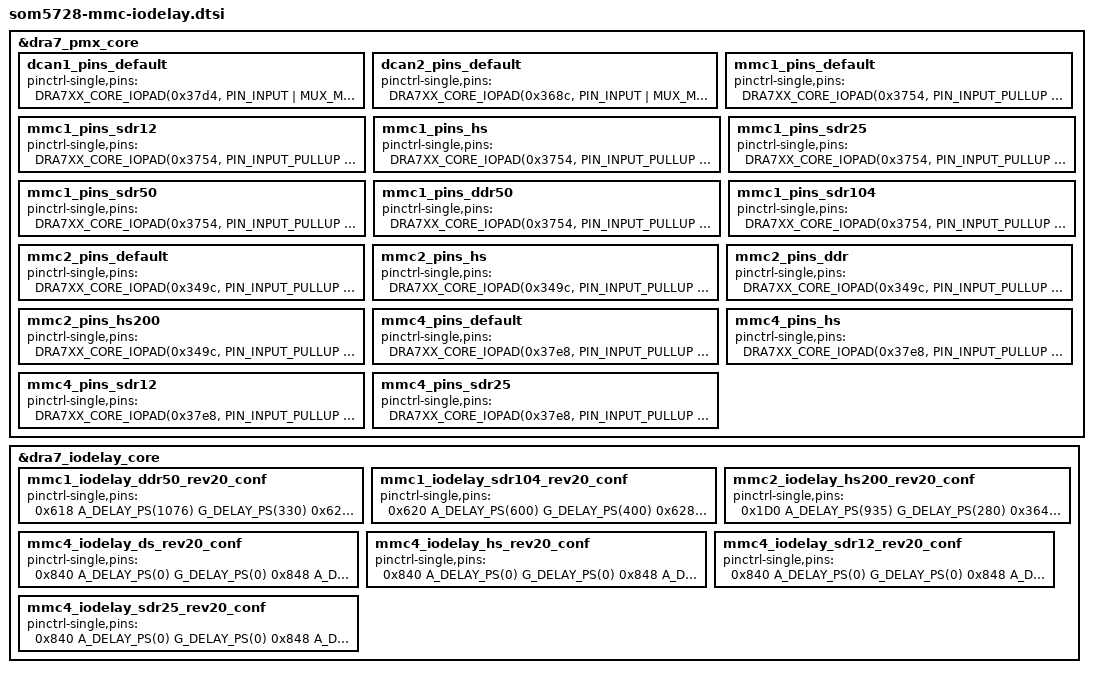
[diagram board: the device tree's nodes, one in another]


// maybe we put all the GPIOS here as defines ?



&dra7_pmx_core {

	dcan1_pins_default: dcan1_pins_default {  
		pinctrl-single,pins = <
			DRA7XX_CORE_IOPAD(0x37d4, PIN_INPUT | MUX_MODE15) 	/* (Errata i893) dcan1_rx.dcan1_rx */
			DRA7XX_CORE_IOPAD(0x37d0, PIN_OUTPUT | MUX_MODE0) 	/* dcan1_tx.dcan1_tx */
		>;
	};

	dcan2_pins_default: dcan2_pins_default {
		pinctrl-single,pins = <
			DRA7XX_CORE_IOPAD(0x368c, PIN_INPUT | MUX_MODE15) 	/* (Errata i893) gpio6_15.dcan2_rx */
			DRA7XX_CORE_IOPAD(0x3688, PIN_OUTPUT | MUX_MODE2) 	/* gpio6_14.dcan2_tx */
		>;
	};

	mmc1_pins_default: mmc1_pins_default {
		pinctrl-single,pins = <
			DRA7XX_CORE_IOPAD(0x3754, PIN_INPUT_PULLUP | MUX_MODE0) 	/* mmc1_clk.mmc1_clk */
			DRA7XX_CORE_IOPAD(0x3758, PIN_INPUT_PULLUP | MUX_MODE0) 	/* mmc1_cmd.mmc1_cmd */
			DRA7XX_CORE_IOPAD(0x375c, PIN_INPUT_PULLUP | MUX_MODE0) 	/* mmc1_dat0.mmc1_dat0 */
			DRA7XX_CORE_IOPAD(0x3760, PIN_INPUT_PULLUP | MUX_MODE0) 	/* mmc1_dat1.mmc1_dat1 */
			DRA7XX_CORE_IOPAD(0x3764, PIN_INPUT_PULLUP | MUX_MODE0) 	/* mmc1_dat2.mmc1_dat2 */
			DRA7XX_CORE_IOPAD(0x3768, PIN_INPUT_PULLUP | MUX_MODE0) 	/* mmc1_dat3.mmc1_dat3 */
			DRA7XX_CORE_IOPAD(0x376c, PIN_INPUT_PULLUP | MUX_MODE0) 	/* mmc1_sdcd.mmc1_sdcd */
		>;
	};

	mmc1_pins_sdr12: mmc1_pins_sdr12 {
		pinctrl-single,pins = <
			DRA7XX_CORE_IOPAD(0x3754, PIN_INPUT_PULLUP | MUX_MODE0) 	/* mmc1_clk.mmc1_clk */
			DRA7XX_CORE_IOPAD(0x3758, PIN_INPUT_PULLUP | MUX_MODE0) 	/* mmc1_cmd.mmc1_cmd */
			DRA7XX_CORE_IOPAD(0x375c, PIN_INPUT_PULLUP | MUX_MODE0) 	/* mmc1_dat0.mmc1_dat0 */
			DRA7XX_CORE_IOPAD(0x3760, PIN_INPUT_PULLUP | MUX_MODE0) 	/* mmc1_dat1.mmc1_dat1 */
			DRA7XX_CORE_IOPAD(0x3764, PIN_INPUT_PULLUP | MUX_MODE0) 	/* mmc1_dat2.mmc1_dat2 */
			DRA7XX_CORE_IOPAD(0x3768, PIN_INPUT_PULLUP | MUX_MODE0) 	/* mmc1_dat3.mmc1_dat3 */
			DRA7XX_CORE_IOPAD(0x376c, PIN_INPUT_PULLUP | MUX_MODE0) 	/* mmc1_sdcd.mmc1_sdcd */
		>;
	};

    
    mmc1_pins_hs: mmc1_pins_hs {
		pinctrl-single,pins = <
			DRA7XX_CORE_IOPAD(0x3754, PIN_INPUT_PULLUP | MUX_VIRTUAL_MODE11 | MUX_MODE0) 	/* mmc1_clk.mmc1_clk */
			DRA7XX_CORE_IOPAD(0x3758, PIN_INPUT_PULLUP | MUX_VIRTUAL_MODE11 | MUX_MODE0) 	/* mmc1_cmd.mmc1_cmd */
			DRA7XX_CORE_IOPAD(0x375c, PIN_INPUT_PULLUP | MUX_VIRTUAL_MODE11 | MUX_MODE0) 	/* mmc1_dat0.mmc1_dat0 */
			DRA7XX_CORE_IOPAD(0x3760, PIN_INPUT_PULLUP | MUX_VIRTUAL_MODE11 | MUX_MODE0) 	/* mmc1_dat1.mmc1_dat1 */
			DRA7XX_CORE_IOPAD(0x3764, PIN_INPUT_PULLUP | MUX_VIRTUAL_MODE11 | MUX_MODE0) 	/* mmc1_dat2.mmc1_dat2 */
			DRA7XX_CORE_IOPAD(0x3768, PIN_INPUT_PULLUP | MUX_VIRTUAL_MODE11 | MUX_MODE0) 	/* mmc1_dat3.mmc1_dat3 */
		>;
	};
    
	mmc1_pins_sdr25: mmc1_pins_sdr25 {
		pinctrl-single,pins = <
			DRA7XX_CORE_IOPAD(0x3754, PIN_INPUT_PULLUP | MUX_VIRTUAL_MODE11 | MUX_MODE0) 	/* mmc1_clk.mmc1_clk */
			DRA7XX_CORE_IOPAD(0x3758, PIN_INPUT_PULLUP | MUX_VIRTUAL_MODE11 | MUX_MODE0) 	/* mmc1_cmd.mmc1_cmd */
			DRA7XX_CORE_IOPAD(0x375c, PIN_INPUT_PULLUP | MUX_VIRTUAL_MODE11 | MUX_MODE0) 	/* mmc1_dat0.mmc1_dat0 */
			DRA7XX_CORE_IOPAD(0x3760, PIN_INPUT_PULLUP | MUX_VIRTUAL_MODE11 | MUX_MODE0) 	/* mmc1_dat1.mmc1_dat1 */
			DRA7XX_CORE_IOPAD(0x3764, PIN_INPUT_PULLUP | MUX_VIRTUAL_MODE11 | MUX_MODE0) 	/* mmc1_dat2.mmc1_dat2 */
			DRA7XX_CORE_IOPAD(0x3768, PIN_INPUT_PULLUP | MUX_VIRTUAL_MODE11 | MUX_MODE0) 	/* mmc1_dat3.mmc1_dat3 */
		>;
	};    
    
    mmc1_pins_sdr50: mmc1_pins_sdr50 {
		pinctrl-single,pins = <
			DRA7XX_CORE_IOPAD(0x3754, PIN_INPUT_PULLUP | MUX_VIRTUAL_MODE10 | MUX_MODE0) 	/* mmc1_clk.mmc1_clk */
			DRA7XX_CORE_IOPAD(0x3758, PIN_INPUT_PULLUP | MUX_VIRTUAL_MODE10 | MUX_MODE0) 	/* mmc1_cmd.mmc1_cmd */
			DRA7XX_CORE_IOPAD(0x375c, PIN_INPUT_PULLUP | MUX_VIRTUAL_MODE10 | MUX_MODE0) 	/* mmc1_dat0.mmc1_dat0 */
			DRA7XX_CORE_IOPAD(0x3760, PIN_INPUT_PULLUP | MUX_VIRTUAL_MODE10 | MUX_MODE0) 	/* mmc1_dat1.mmc1_dat1 */
			DRA7XX_CORE_IOPAD(0x3764, PIN_INPUT_PULLUP | MUX_VIRTUAL_MODE10 | MUX_MODE0) 	/* mmc1_dat2.mmc1_dat2 */
			DRA7XX_CORE_IOPAD(0x3768, PIN_INPUT_PULLUP | MUX_VIRTUAL_MODE10 | MUX_MODE0) 	/* mmc1_dat3.mmc1_dat3 */
		>;
	};
    
    
	mmc1_pins_ddr50: mmc1_pins_ddr50 {
		pinctrl-single,pins = <
			DRA7XX_CORE_IOPAD(0x3754, PIN_INPUT_PULLUP | MODE_SELECT | MUX_MODE0) 	/* mmc1_clk.mmc1_clk */
			DRA7XX_CORE_IOPAD(0x3758, PIN_INPUT_PULLUP | MODE_SELECT | MUX_MODE0) 	/* mmc1_cmd.mmc1_cmd */
			DRA7XX_CORE_IOPAD(0x375c, PIN_INPUT_PULLUP | MODE_SELECT | MUX_MODE0) 	/* mmc1_dat0.mmc1_dat0 */
			DRA7XX_CORE_IOPAD(0x3760, PIN_INPUT_PULLUP | MODE_SELECT | MUX_MODE0) 	/* mmc1_dat1.mmc1_dat1 */
			DRA7XX_CORE_IOPAD(0x3764, PIN_INPUT_PULLUP | MODE_SELECT | MUX_MODE0) 	/* mmc1_dat2.mmc1_dat2 */
			DRA7XX_CORE_IOPAD(0x3768, PIN_INPUT_PULLUP | MODE_SELECT | MUX_MODE0) 	/* mmc1_dat3.mmc1_dat3 */
		>;
	};


	mmc1_pins_sdr104: mmc1_pins_sdr104 {
		pinctrl-single,pins = <
			DRA7XX_CORE_IOPAD(0x3754, PIN_INPUT_PULLUP | MODE_SELECT | MUX_MODE0) 	/* mmc1_clk.mmc1_clk */
			DRA7XX_CORE_IOPAD(0x3758, PIN_INPUT_PULLUP | MODE_SELECT | MUX_MODE0) 	/* mmc1_cmd.mmc1_cmd */
			DRA7XX_CORE_IOPAD(0x375c, PIN_INPUT_PULLUP | MODE_SELECT | MUX_MODE0) 	/* mmc1_dat0.mmc1_dat0 */
			DRA7XX_CORE_IOPAD(0x3760, PIN_INPUT_PULLUP | MODE_SELECT | MUX_MODE0) 	/* mmc1_dat1.mmc1_dat1 */
			DRA7XX_CORE_IOPAD(0x3764, PIN_INPUT_PULLUP | MODE_SELECT | MUX_MODE0) 	/* mmc1_dat2.mmc1_dat2 */
			DRA7XX_CORE_IOPAD(0x3768, PIN_INPUT_PULLUP | MODE_SELECT | MUX_MODE0) 	/* mmc1_dat3.mmc1_dat3 */
		>;
	};
    

    
    
    

	mmc2_pins_default: mmc2_pins_default {
		pinctrl-single,pins = <
			DRA7XX_CORE_IOPAD(0x349c, PIN_INPUT_PULLUP | MUX_MODE1) 	/* gpmc_a23.mmc2_clk */
			DRA7XX_CORE_IOPAD(0x34b0, PIN_INPUT_PULLUP | MUX_MODE1) 	/* gpmc_cs1.mmc2_cmd */
			DRA7XX_CORE_IOPAD(0x34a0, PIN_INPUT_PULLUP | MUX_MODE1) 	/* gpmc_a24.mmc2_dat0 */
			DRA7XX_CORE_IOPAD(0x34a4, PIN_INPUT_PULLUP | MUX_MODE1) 	/* gpmc_a25.mmc2_dat1 */
			DRA7XX_CORE_IOPAD(0x34a8, PIN_INPUT_PULLUP | MUX_MODE1) 	/* gpmc_a26.mmc2_dat2 */
			DRA7XX_CORE_IOPAD(0x34ac, PIN_INPUT_PULLUP | MUX_MODE1) 	/* gpmc_a27.mmc2_dat3 */
			DRA7XX_CORE_IOPAD(0x348c, PIN_INPUT_PULLUP | MUX_MODE1) 	/* gpmc_a19.mmc2_dat4 */
			DRA7XX_CORE_IOPAD(0x3490, PIN_INPUT_PULLUP | MUX_MODE1) 	/* gpmc_a20.mmc2_dat5 */
			DRA7XX_CORE_IOPAD(0x3494, PIN_INPUT_PULLUP | MUX_MODE1) 	/* gpmc_a21.mmc2_dat6 */
			DRA7XX_CORE_IOPAD(0x3498, PIN_INPUT_PULLUP | MUX_MODE1) 	/* gpmc_a22.mmc2_dat7 */
		>;
	};

	mmc2_pins_hs: mmc2_pins_hs {
		pinctrl-single,pins = <
			DRA7XX_CORE_IOPAD(0x349c, PIN_INPUT_PULLUP | MUX_MODE1) 	/* gpmc_a23.mmc2_clk */
			DRA7XX_CORE_IOPAD(0x34b0, PIN_INPUT_PULLUP | MUX_MODE1) 	/* gpmc_cs1.mmc2_cmd */
			DRA7XX_CORE_IOPAD(0x34a0, PIN_INPUT_PULLUP | MUX_MODE1) 	/* gpmc_a24.mmc2_dat0 */
			DRA7XX_CORE_IOPAD(0x34a4, PIN_INPUT_PULLUP | MUX_MODE1) 	/* gpmc_a25.mmc2_dat1 */
			DRA7XX_CORE_IOPAD(0x34a8, PIN_INPUT_PULLUP | MUX_MODE1) 	/* gpmc_a26.mmc2_dat2 */
			DRA7XX_CORE_IOPAD(0x34ac, PIN_INPUT_PULLUP | MUX_MODE1) 	/* gpmc_a27.mmc2_dat3 */
			DRA7XX_CORE_IOPAD(0x348c, PIN_INPUT_PULLUP | MUX_MODE1) 	/* gpmc_a19.mmc2_dat4 */
			DRA7XX_CORE_IOPAD(0x3490, PIN_INPUT_PULLUP | MUX_MODE1) 	/* gpmc_a20.mmc2_dat5 */
			DRA7XX_CORE_IOPAD(0x3494, PIN_INPUT_PULLUP | MUX_MODE1) 	/* gpmc_a21.mmc2_dat6 */
			DRA7XX_CORE_IOPAD(0x3498, PIN_INPUT_PULLUP | MUX_MODE1) 	/* gpmc_a22.mmc2_dat7 */
		>;
	};

	mmc2_pins_ddr: mmc2_pins_ddr {
		pinctrl-single,pins = <
			DRA7XX_CORE_IOPAD(0x349c, PIN_INPUT_PULLUP | MUX_MODE1) 	/* gpmc_a23.mmc2_clk */
			DRA7XX_CORE_IOPAD(0x34b0, PIN_INPUT_PULLUP | MUX_MODE1) 	/* gpmc_cs1.mmc2_cmd */
			DRA7XX_CORE_IOPAD(0x34a0, PIN_INPUT_PULLUP | MUX_MODE1) 	/* gpmc_a24.mmc2_dat0 */
			DRA7XX_CORE_IOPAD(0x34a4, PIN_INPUT_PULLUP | MUX_MODE1) 	/* gpmc_a25.mmc2_dat1 */
			DRA7XX_CORE_IOPAD(0x34a8, PIN_INPUT_PULLUP | MUX_MODE1) 	/* gpmc_a26.mmc2_dat2 */
			DRA7XX_CORE_IOPAD(0x34ac, PIN_INPUT_PULLUP | MUX_MODE1) 	/* gpmc_a27.mmc2_dat3 */
			DRA7XX_CORE_IOPAD(0x348c, PIN_INPUT_PULLUP | MUX_MODE1) 	/* gpmc_a19.mmc2_dat4 */
			DRA7XX_CORE_IOPAD(0x3490, PIN_INPUT_PULLUP | MUX_MODE1) 	/* gpmc_a20.mmc2_dat5 */
			DRA7XX_CORE_IOPAD(0x3494, PIN_INPUT_PULLUP | MUX_MODE1) 	/* gpmc_a21.mmc2_dat6 */
			DRA7XX_CORE_IOPAD(0x3498, PIN_INPUT_PULLUP | MUX_MODE1) 	/* gpmc_a22.mmc2_dat7 */
		>;
	};

	mmc2_pins_hs200: mmc2_pins_hs200 {
		pinctrl-single,pins = <
			DRA7XX_CORE_IOPAD(0x349c, PIN_INPUT_PULLUP | MODE_SELECT | MUX_MODE1) 	/* gpmc_a23.mmc2_clk */
			DRA7XX_CORE_IOPAD(0x34b0, PIN_INPUT_PULLUP | MODE_SELECT | MUX_MODE1) 	/* gpmc_cs1.mmc2_cmd */
			DRA7XX_CORE_IOPAD(0x34a0, PIN_INPUT_PULLUP | MODE_SELECT | MUX_MODE1) 	/* gpmc_a24.mmc2_dat0 */
			DRA7XX_CORE_IOPAD(0x34a4, PIN_INPUT_PULLUP | MODE_SELECT | MUX_MODE1) 	/* gpmc_a25.mmc2_dat1 */
			DRA7XX_CORE_IOPAD(0x34a8, PIN_INPUT_PULLUP | MODE_SELECT | MUX_MODE1) 	/* gpmc_a26.mmc2_dat2 */
			DRA7XX_CORE_IOPAD(0x34ac, PIN_INPUT_PULLUP | MODE_SELECT | MUX_MODE1) 	/* gpmc_a27.mmc2_dat3 */
			DRA7XX_CORE_IOPAD(0x348c, PIN_INPUT_PULLUP | MODE_SELECT | MUX_MODE1) 	/* gpmc_a19.mmc2_dat4 */
			DRA7XX_CORE_IOPAD(0x3490, PIN_INPUT_PULLUP | MODE_SELECT | MUX_MODE1) 	/* gpmc_a20.mmc2_dat5 */
			DRA7XX_CORE_IOPAD(0x3494, PIN_INPUT_PULLUP | MODE_SELECT | MUX_MODE1) 	/* gpmc_a21.mmc2_dat6 */
			DRA7XX_CORE_IOPAD(0x3498, PIN_INPUT_PULLUP | MODE_SELECT | MUX_MODE1) 	/* gpmc_a22.mmc2_dat7 */
		>;
	};

	mmc4_pins_default: mmc4_pins_default {
		pinctrl-single,pins = <
			DRA7XX_CORE_IOPAD(0x37e8, PIN_INPUT_PULLUP | MODE_SELECT | MUX_MODE3) 	/* uart1_ctsn.mmc4_clk */
			DRA7XX_CORE_IOPAD(0x37ec, PIN_INPUT_PULLUP | MODE_SELECT | MUX_MODE3) 	/* uart1_rtsn.mmc4_cmd */
			DRA7XX_CORE_IOPAD(0x37f0, PIN_INPUT_PULLUP | MODE_SELECT | MUX_MODE3) 	/* uart2_rxd.mmc4_dat0 */
			DRA7XX_CORE_IOPAD(0x37f4, PIN_INPUT_PULLUP | MODE_SELECT | MUX_MODE3) 	/* uart2_txd.mmc4_dat1 */
			DRA7XX_CORE_IOPAD(0x37f8, PIN_INPUT_PULLUP | MODE_SELECT | MUX_MODE3) 	/* uart2_ctsn.mmc4_dat2 */
			DRA7XX_CORE_IOPAD(0x37fc, PIN_INPUT_PULLUP | MODE_SELECT | MUX_MODE3) 	/* uart2_rtsn.mmc4_dat3 */
		>;
	};

	mmc4_pins_hs: mmc4_pins_hs {
		pinctrl-single,pins = <
			DRA7XX_CORE_IOPAD(0x37e8, PIN_INPUT_PULLUP | MODE_SELECT | MUX_MODE3) 	/* uart1_ctsn.mmc4_clk */
			DRA7XX_CORE_IOPAD(0x37ec, PIN_INPUT_PULLUP | MODE_SELECT | MUX_MODE3) 	/* uart1_rtsn.mmc4_cmd */
			DRA7XX_CORE_IOPAD(0x37f0, PIN_INPUT_PULLUP | MODE_SELECT | MUX_MODE3) 	/* uart2_rxd.mmc4_dat0 */
			DRA7XX_CORE_IOPAD(0x37f4, PIN_INPUT_PULLUP | MODE_SELECT | MUX_MODE3) 	/* uart2_txd.mmc4_dat1 */
			DRA7XX_CORE_IOPAD(0x37f8, PIN_INPUT_PULLUP | MODE_SELECT | MUX_MODE3) 	/* uart2_ctsn.mmc4_dat2 */
			DRA7XX_CORE_IOPAD(0x37fc, PIN_INPUT_PULLUP | MODE_SELECT | MUX_MODE3) 	/* uart2_rtsn.mmc4_dat3 */
		>;
	};

	mmc4_pins_sdr12: mmc4_pins_sdr12 {
		pinctrl-single,pins = <
			DRA7XX_CORE_IOPAD(0x37e8, PIN_INPUT_PULLUP | MODE_SELECT | MUX_MODE3) 	/* uart1_ctsn.mmc4_clk */
			DRA7XX_CORE_IOPAD(0x37ec, PIN_INPUT_PULLUP | MODE_SELECT | MUX_MODE3) 	/* uart1_rtsn.mmc4_cmd */
			DRA7XX_CORE_IOPAD(0x37f0, PIN_INPUT_PULLUP | MODE_SELECT | MUX_MODE3) 	/* uart2_rxd.mmc4_dat0 */
			DRA7XX_CORE_IOPAD(0x37f4, PIN_INPUT_PULLUP | MODE_SELECT | MUX_MODE3) 	/* uart2_txd.mmc4_dat1 */
			DRA7XX_CORE_IOPAD(0x37f8, PIN_INPUT_PULLUP | MODE_SELECT | MUX_MODE3) 	/* uart2_ctsn.mmc4_dat2 */
			DRA7XX_CORE_IOPAD(0x37fc, PIN_INPUT_PULLUP | MODE_SELECT | MUX_MODE3) 	/* uart2_rtsn.mmc4_dat3 */
		>;
	};

	mmc4_pins_sdr25: mmc4_pins_sdr25 {
		pinctrl-single,pins = <
			DRA7XX_CORE_IOPAD(0x37e8, PIN_INPUT_PULLUP | MODE_SELECT | MUX_MODE3) 	/* uart1_ctsn.mmc4_clk */
			DRA7XX_CORE_IOPAD(0x37ec, PIN_INPUT_PULLUP | MODE_SELECT | MUX_MODE3) 	/* uart1_rtsn.mmc4_cmd */
			DRA7XX_CORE_IOPAD(0x37f0, PIN_INPUT_PULLUP | MODE_SELECT | MUX_MODE3) 	/* uart2_rxd.mmc4_dat0 */
			DRA7XX_CORE_IOPAD(0x37f4, PIN_INPUT_PULLUP | MODE_SELECT | MUX_MODE3) 	/* uart2_txd.mmc4_dat1 */
			DRA7XX_CORE_IOPAD(0x37f8, PIN_INPUT_PULLUP | MODE_SELECT | MUX_MODE3) 	/* uart2_ctsn.mmc4_dat2 */
			DRA7XX_CORE_IOPAD(0x37fc, PIN_INPUT_PULLUP | MODE_SELECT | MUX_MODE3) 	/* uart2_rtsn.mmc4_dat3 */
		>;
	};

};


/* * DEVICE TREE FORMAT IODELAY * */

&dra7_iodelay_core {

	mmc1_iodelay_ddr50_rev20_conf: mmc1_iodelay_ddr50_rev20_conf {
		pinctrl-single,pins = <
			0x618 A_DELAY_PS(1076)  G_DELAY_PS(330) 	/* CFG_MMC1_CLK_IN */
			0x620 A_DELAY_PS(1271)  G_DELAY_PS(0) 	/* CFG_MMC1_CLK_OUT */
			0x624 A_DELAY_PS(722)  G_DELAY_PS(0) 	/* CFG_MMC1_CMD_IN */
			0x628 A_DELAY_PS(0)  G_DELAY_PS(0) 	/* CFG_MMC1_CMD_OEN */
			0x62C A_DELAY_PS(0)  G_DELAY_PS(0) 	/* CFG_MMC1_CMD_OUT */
			0x630 A_DELAY_PS(751)  G_DELAY_PS(0) 	/* CFG_MMC1_DAT0_IN */
			0x634 A_DELAY_PS(0)  G_DELAY_PS(0) 	/* CFG_MMC1_DAT0_OEN */
			0x638 A_DELAY_PS(20)  G_DELAY_PS(0) 	/* CFG_MMC1_DAT0_OUT */
			0x63C A_DELAY_PS(256)  G_DELAY_PS(0) 	/* CFG_MMC1_DAT1_IN */
			0x640 A_DELAY_PS(0)  G_DELAY_PS(0) 	/* CFG_MMC1_DAT1_OEN */
			0x644 A_DELAY_PS(0)  G_DELAY_PS(0) 	/* CFG_MMC1_DAT1_OUT */
			0x648 A_DELAY_PS(263)  G_DELAY_PS(0) 	/* CFG_MMC1_DAT2_IN */
			0x64C A_DELAY_PS(0)  G_DELAY_PS(0) 	/* CFG_MMC1_DAT2_OEN */
			0x650 A_DELAY_PS(0)  G_DELAY_PS(0) 	/* CFG_MMC1_DAT2_OUT */
			0x654 A_DELAY_PS(0)  G_DELAY_PS(0) 	/* CFG_MMC1_DAT3_IN */
			0x658 A_DELAY_PS(0)  G_DELAY_PS(0) 	/* CFG_MMC1_DAT3_OEN */
			0x65C A_DELAY_PS(0)  G_DELAY_PS(0) 	/* CFG_MMC1_DAT3_OUT */
		>;
	};

	mmc1_iodelay_sdr104_rev20_conf: mmc1_iodelay_sdr104_rev20_conf {
		pinctrl-single,pins = <
			0x620 A_DELAY_PS(600)  G_DELAY_PS(400) 	/* CFG_MMC1_CLK_OUT */
			0x628 A_DELAY_PS(0)  G_DELAY_PS(0) 	/* CFG_MMC1_CMD_OEN */
			0x62C A_DELAY_PS(0)  G_DELAY_PS(0) 	/* CFG_MMC1_CMD_OUT */
			0x634 A_DELAY_PS(0)  G_DELAY_PS(0) 	/* CFG_MMC1_DAT0_OEN */
			0x638 A_DELAY_PS(30)  G_DELAY_PS(0) 	/* CFG_MMC1_DAT0_OUT */
			0x640 A_DELAY_PS(0)  G_DELAY_PS(0) 	/* CFG_MMC1_DAT1_OEN */
			0x644 A_DELAY_PS(0)  G_DELAY_PS(0) 	/* CFG_MMC1_DAT1_OUT */
			0x64C A_DELAY_PS(0)  G_DELAY_PS(0) 	/* CFG_MMC1_DAT2_OEN */
			0x650 A_DELAY_PS(0)  G_DELAY_PS(0) 	/* CFG_MMC1_DAT2_OUT */
			0x658 A_DELAY_PS(0)  G_DELAY_PS(0) 	/* CFG_MMC1_DAT3_OEN */
			0x65C A_DELAY_PS(0)  G_DELAY_PS(0) 	/* CFG_MMC1_DAT3_OUT */
		>;
	};

	mmc2_iodelay_hs200_rev20_conf: mmc2_iodelay_hs200_rev20_conf {
		pinctrl-single,pins = <
			0x1D0 A_DELAY_PS(935)  G_DELAY_PS(280) 	/* CFG_GPMC_A23_OUT */
			0x364 A_DELAY_PS(684)  G_DELAY_PS(0) 	/* CFG_GPMC_CS1_OEN */
			0x368 A_DELAY_PS(76)  G_DELAY_PS(0) 	/* CFG_GPMC_CS1_OUT */
			0x1D8 A_DELAY_PS(621)  G_DELAY_PS(0) 	/* CFG_GPMC_A24_OEN */
			0x1DC A_DELAY_PS(0)  G_DELAY_PS(0) 	/* CFG_GPMC_A24_OUT */
			0x1E4 A_DELAY_PS(183)  G_DELAY_PS(0) 	/* CFG_GPMC_A25_OEN */
			0x1E8 A_DELAY_PS(0)  G_DELAY_PS(0) 	/* CFG_GPMC_A25_OUT */
			0x1F0 A_DELAY_PS(467)  G_DELAY_PS(0) 	/* CFG_GPMC_A26_OEN */
			0x1F4 A_DELAY_PS(0)  G_DELAY_PS(0) 	/* CFG_GPMC_A26_OUT */
			0x1FC A_DELAY_PS(262)  G_DELAY_PS(0) 	/* CFG_GPMC_A27_OEN */
			0x200 A_DELAY_PS(46)  G_DELAY_PS(0) 	/* CFG_GPMC_A27_OUT */
			0x190 A_DELAY_PS(274)  G_DELAY_PS(0) 	/* CFG_GPMC_A19_OEN */
			0x194 A_DELAY_PS(162)  G_DELAY_PS(0) 	/* CFG_GPMC_A19_OUT */
			0x1A8 A_DELAY_PS(401)  G_DELAY_PS(0) 	/* CFG_GPMC_A20_OEN */
			0x1AC A_DELAY_PS(73)  G_DELAY_PS(0) 	/* CFG_GPMC_A20_OUT */
			0x1B4 A_DELAY_PS(465)  G_DELAY_PS(0) 	/* CFG_GPMC_A21_OEN */
			0x1B8 A_DELAY_PS(115)  G_DELAY_PS(0) 	/* CFG_GPMC_A21_OUT */
			0x1C0 A_DELAY_PS(633)  G_DELAY_PS(0) 	/* CFG_GPMC_A22_OEN */
			0x1C4 A_DELAY_PS(47)  G_DELAY_PS(0) 	/* CFG_GPMC_A22_OUT */
		>;
	};

	mmc4_iodelay_ds_rev20_conf: mmc4_iodelay_ds_rev20_conf {
		pinctrl-single,pins = <
			0x840 A_DELAY_PS(0)  G_DELAY_PS(0) 	/* CFG_UART1_CTSN_IN */
			0x848 A_DELAY_PS(0)  G_DELAY_PS(0) 	/* CFG_UART1_CTSN_OUT */
			0x84C A_DELAY_PS(307)  G_DELAY_PS(0) 	/* CFG_UART1_RTSN_IN */
			0x850 A_DELAY_PS(0)  G_DELAY_PS(0) 	/* CFG_UART1_RTSN_OEN */
			0x854 A_DELAY_PS(0)  G_DELAY_PS(0) 	/* CFG_UART1_RTSN_OUT */
			0x888 A_DELAY_PS(683)  G_DELAY_PS(0) 	/* CFG_UART2_RXD_IN */
			0x88C A_DELAY_PS(0)  G_DELAY_PS(0) 	/* CFG_UART2_RXD_OEN */
			0x890 A_DELAY_PS(0)  G_DELAY_PS(0) 	/* CFG_UART2_RXD_OUT */
			0x894 A_DELAY_PS(835)  G_DELAY_PS(0) 	/* CFG_UART2_TXD_IN */
			0x898 A_DELAY_PS(0)  G_DELAY_PS(0) 	/* CFG_UART2_TXD_OEN */
			0x89C A_DELAY_PS(0)  G_DELAY_PS(0) 	/* CFG_UART2_TXD_OUT */
			0x870 A_DELAY_PS(785)  G_DELAY_PS(0) 	/* CFG_UART2_CTSN_IN */
			0x874 A_DELAY_PS(0)  G_DELAY_PS(0) 	/* CFG_UART2_CTSN_OEN */
			0x878 A_DELAY_PS(0)  G_DELAY_PS(0) 	/* CFG_UART2_CTSN_OUT */
			0x87C A_DELAY_PS(613)  G_DELAY_PS(0) 	/* CFG_UART2_RTSN_IN */
			0x880 A_DELAY_PS(0)  G_DELAY_PS(0) 	/* CFG_UART2_RTSN_OEN */
			0x884 A_DELAY_PS(0)  G_DELAY_PS(0) 	/* CFG_UART2_RTSN_OUT */
		>;
	};

	mmc4_iodelay_hs_rev20_conf: mmc4_iodelay_hs_rev20_conf {
		pinctrl-single,pins = <
			0x840 A_DELAY_PS(0)  G_DELAY_PS(0) 	/* CFG_UART1_CTSN_IN */
			0x848 A_DELAY_PS(1147)  G_DELAY_PS(0) 	/* CFG_UART1_CTSN_OUT */
			0x84C A_DELAY_PS(1834)  G_DELAY_PS(0) 	/* CFG_UART1_RTSN_IN */
			0x850 A_DELAY_PS(0)  G_DELAY_PS(0) 	/* CFG_UART1_RTSN_OEN */
			0x854 A_DELAY_PS(0)  G_DELAY_PS(0) 	/* CFG_UART1_RTSN_OUT */
			0x888 A_DELAY_PS(1935)  G_DELAY_PS(128) 	/* CFG_UART2_RXD_IN */
			0x88C A_DELAY_PS(0)  G_DELAY_PS(0) 	/* CFG_UART2_RXD_OEN */
			0x890 A_DELAY_PS(0)  G_DELAY_PS(0) 	/* CFG_UART2_RXD_OUT */
			0x894 A_DELAY_PS(2172)  G_DELAY_PS(44) 	/* CFG_UART2_TXD_IN */
			0x898 A_DELAY_PS(0)  G_DELAY_PS(0) 	/* CFG_UART2_TXD_OEN */
			0x89C A_DELAY_PS(0)  G_DELAY_PS(0) 	/* CFG_UART2_TXD_OUT */
			0x870 A_DELAY_PS(2165)  G_DELAY_PS(0) 	/* CFG_UART2_CTSN_IN */
			0x874 A_DELAY_PS(0)  G_DELAY_PS(0) 	/* CFG_UART2_CTSN_OEN */
			0x878 A_DELAY_PS(0)  G_DELAY_PS(0) 	/* CFG_UART2_CTSN_OUT */
			0x87C A_DELAY_PS(1929)  G_DELAY_PS(64) 	/* CFG_UART2_RTSN_IN */
			0x880 A_DELAY_PS(0)  G_DELAY_PS(0) 	/* CFG_UART2_RTSN_OEN */
			0x884 A_DELAY_PS(0)  G_DELAY_PS(0) 	/* CFG_UART2_RTSN_OUT */
		>;
	};

	mmc4_iodelay_sdr12_rev20_conf: mmc4_iodelay_sdr12_rev20_conf {
		pinctrl-single,pins = <
			0x840 A_DELAY_PS(0)  G_DELAY_PS(0) 	/* CFG_UART1_CTSN_IN */
			0x848 A_DELAY_PS(1147)  G_DELAY_PS(0) 	/* CFG_UART1_CTSN_OUT */
			0x84C A_DELAY_PS(1834)  G_DELAY_PS(0) 	/* CFG_UART1_RTSN_IN */
			0x850 A_DELAY_PS(0)  G_DELAY_PS(0) 	/* CFG_UART1_RTSN_OEN */
			0x854 A_DELAY_PS(0)  G_DELAY_PS(0) 	/* CFG_UART1_RTSN_OUT */
			0x888 A_DELAY_PS(1935)  G_DELAY_PS(128) 	/* CFG_UART2_RXD_IN */
			0x88C A_DELAY_PS(0)  G_DELAY_PS(0) 	/* CFG_UART2_RXD_OEN */
			0x890 A_DELAY_PS(0)  G_DELAY_PS(0) 	/* CFG_UART2_RXD_OUT */
			0x894 A_DELAY_PS(2172)  G_DELAY_PS(44) 	/* CFG_UART2_TXD_IN */
			0x898 A_DELAY_PS(0)  G_DELAY_PS(0) 	/* CFG_UART2_TXD_OEN */
			0x89C A_DELAY_PS(0)  G_DELAY_PS(0) 	/* CFG_UART2_TXD_OUT */
			0x870 A_DELAY_PS(2165)  G_DELAY_PS(0) 	/* CFG_UART2_CTSN_IN */
			0x874 A_DELAY_PS(0)  G_DELAY_PS(0) 	/* CFG_UART2_CTSN_OEN */
			0x878 A_DELAY_PS(0)  G_DELAY_PS(0) 	/* CFG_UART2_CTSN_OUT */
			0x87C A_DELAY_PS(1929)  G_DELAY_PS(64) 	/* CFG_UART2_RTSN_IN */
			0x880 A_DELAY_PS(0)  G_DELAY_PS(0) 	/* CFG_UART2_RTSN_OEN */
			0x884 A_DELAY_PS(0)  G_DELAY_PS(0) 	/* CFG_UART2_RTSN_OUT */
		>;
	};

	mmc4_iodelay_sdr25_rev20_conf: mmc4_iodelay_sdr25_rev20_conf {
		pinctrl-single,pins = <
			0x840 A_DELAY_PS(0)  G_DELAY_PS(0) 	/* CFG_UART1_CTSN_IN */
			0x848 A_DELAY_PS(1147)  G_DELAY_PS(0) 	/* CFG_UART1_CTSN_OUT */
			0x84C A_DELAY_PS(1834)  G_DELAY_PS(0) 	/* CFG_UART1_RTSN_IN */
			0x850 A_DELAY_PS(0)  G_DELAY_PS(0) 	/* CFG_UART1_RTSN_OEN */
			0x854 A_DELAY_PS(0)  G_DELAY_PS(0) 	/* CFG_UART1_RTSN_OUT */
			0x888 A_DELAY_PS(1935)  G_DELAY_PS(128) 	/* CFG_UART2_RXD_IN */
			0x88C A_DELAY_PS(0)  G_DELAY_PS(0) 	/* CFG_UART2_RXD_OEN */
			0x890 A_DELAY_PS(0)  G_DELAY_PS(0) 	/* CFG_UART2_RXD_OUT */
			0x894 A_DELAY_PS(2172)  G_DELAY_PS(44) 	/* CFG_UART2_TXD_IN */
			0x898 A_DELAY_PS(0)  G_DELAY_PS(0) 	/* CFG_UART2_TXD_OEN */
			0x89C A_DELAY_PS(0)  G_DELAY_PS(0) 	/* CFG_UART2_TXD_OUT */
			0x870 A_DELAY_PS(2165)  G_DELAY_PS(0) 	/* CFG_UART2_CTSN_IN */
			0x874 A_DELAY_PS(0)  G_DELAY_PS(0) 	/* CFG_UART2_CTSN_OEN */
			0x878 A_DELAY_PS(0)  G_DELAY_PS(0) 	/* CFG_UART2_CTSN_OUT   */
			0x87C A_DELAY_PS(1929)  G_DELAY_PS(64) 	/* CFG_UART2_RTSN_IN */
			0x880 A_DELAY_PS(0)  G_DELAY_PS(0) 	/* CFG_UART2_RTSN_OEN */
			0x884 A_DELAY_PS(0)  G_DELAY_PS(0) 	/* CFG_UART2_RTSN_OUT */
		>;
	};

};
